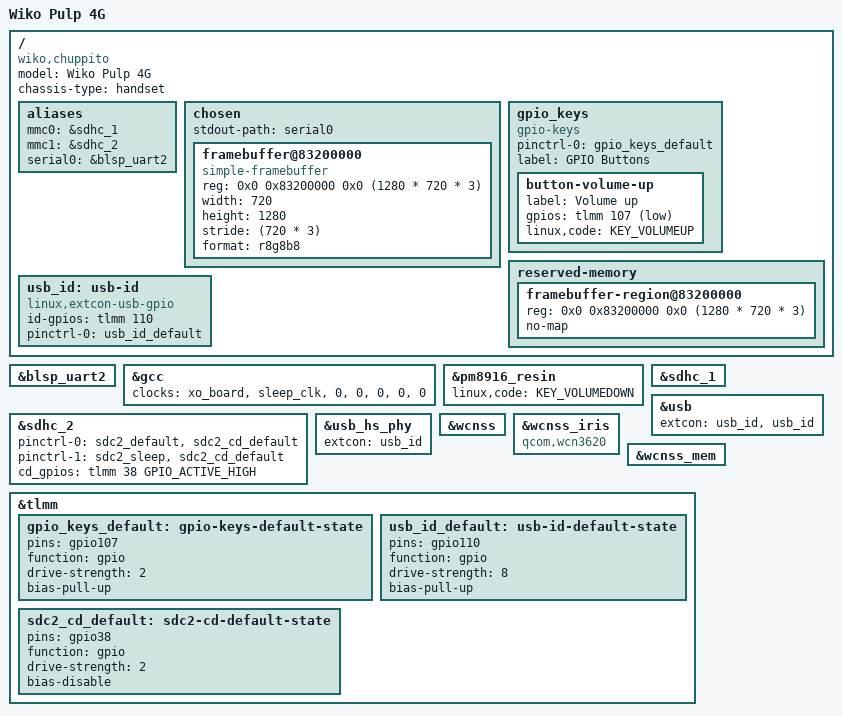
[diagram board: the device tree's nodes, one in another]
// SPDX-License-Identifier: GPL-2.0-only

/dts-v1/;

#include "msm8916-pm8916.dtsi"
#include <dt-bindings/gpio/gpio.h>
#include <dt-bindings/input/input.h>

/ {
	model = "Wiko Pulp 4G";
	compatible = "wiko,chuppito", "qcom,msm8916";
	chassis-type = "handset";

	aliases {
		mmc0 = &sdhc_1; /* eMMC */
		mmc1 = &sdhc_2; /* SD card */
		serial0 = &blsp_uart2;
	};

	chosen {
		#address-cells = <2>;
		#size-cells = <2>;
		ranges;
		stdout-path = "serial0";

		framebuffer@83200000 {
			compatible = "simple-framebuffer";
			reg = <0x0 0x83200000 0x0 (1280 * 720 * 3)>;
			width = <720>;
			height = <1280>;
			stride = <(720 * 3)>;
			format = "r8g8b8";
		};
	};

	gpio_keys {
		compatible = "gpio-keys";
		pinctrl-0 = <&gpio_keys_default>;
		pinctrl-names = "default";
		label = "GPIO Buttons";

		button-volume-up {
			label = "Volume up";
			gpios = <&tlmm 107 GPIO_ACTIVE_LOW>;
			linux,code = <KEY_VOLUMEUP>;
		};
	};


	reserved-memory {
		#address-cells = <2>;
		#size-cells = <2>;
		ranges;

		framebuffer-region@83200000 {
			reg = <0x0 0x83200000 0x0 (1280 * 720 * 3)>;
			no-map;
		};
	};

	usb_id: usb-id {
		compatible = "linux,extcon-usb-gpio";
		id-gpios = <&tlmm 110 GPIO_ACTIVE_HIGH>;
		pinctrl-0 = <&usb_id_default>;
		pinctrl-names = "default";
	};
};

&blsp_uart2 {
	status = "okay";
};

// make sure gcc is probed with display disabled.
&gcc {
	clocks = <&xo_board>, <&sleep_clk>, <0>, <0>, <0>, <0>, <0>;
};

&pm8916_resin {
	linux,code = <KEY_VOLUMEDOWN>;
	status = "okay";
};

&sdhc_1 {
	status = "okay";
};

&sdhc_2 {
	pinctrl-0 = <&sdc2_default>, <&sdc2_cd_default>;
	pinctrl-1 = <&sdc2_sleep>, <&sdc2_cd_default>;
	pinctrl-names = "default", "sleep";
	cd_gpios = <&tlmm 38 GPIO_ACTIVE_HIGH>;
	status = "okay";
};

&usb {
	extcon = <&usb_id>, <&usb_id>;
	status = "okay";
};

&usb_hs_phy {
	extcon = <&usb_id>;
};

&wcnss {
	status = "okay";
};

&wcnss_iris {
	compatible = "qcom,wcn3620";
};

&wcnss_mem {
	status = "okay";
};

&tlmm {
	gpio_keys_default: gpio-keys-default-state {
		pins = "gpio107";
		function = "gpio";
		drive-strength = <2>;
		bias-pull-up;
	};

	usb_id_default: usb-id-default-state {
		pins = "gpio110";
		function = "gpio";
		drive-strength = <8>;
		bias-pull-up;
	};

	sdc2_cd_default: sdc2-cd-default-state {
		pins = "gpio38";
		function = "gpio";
		drive-strength = <2>;
		bias-disable;
	};
};
